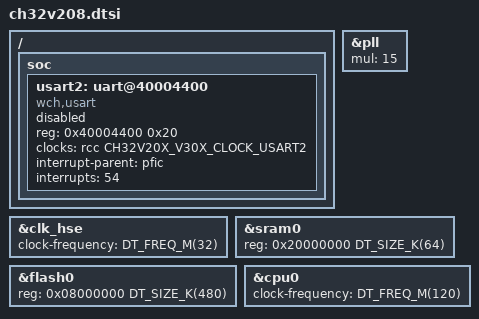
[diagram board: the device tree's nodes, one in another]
/*
 * Copyright (c) 2025 MASSDRIVER EI (massdriver.space)
 *
 * SPDX-License-Identifier: Apache-2.0
 */

#include <wch/qingke-v4c.dtsi>
#include <wch/common/ch32v20x_30x_common.dtsi>

/ {
	soc {
		usart2: uart@40004400 {
			compatible = "wch,usart";
			reg = <0x40004400 0x20>;
			clocks = <&rcc CH32V20X_V30X_CLOCK_USART2>;
			interrupt-parent = <&pfic>;
			interrupts = <54>;
			status = "disabled";
		};
	};
};

&clk_hse {
	clock-frequency = <DT_FREQ_M(32)>;
};

&pll {
	mul = <15>;
};

&sram0 {
	reg = <0x20000000 DT_SIZE_K(64)>;
};

&flash0 {
	reg = <0x08000000 DT_SIZE_K(480)>;
};

&cpu0 {
	clock-frequency = <DT_FREQ_M(120)>;
};
